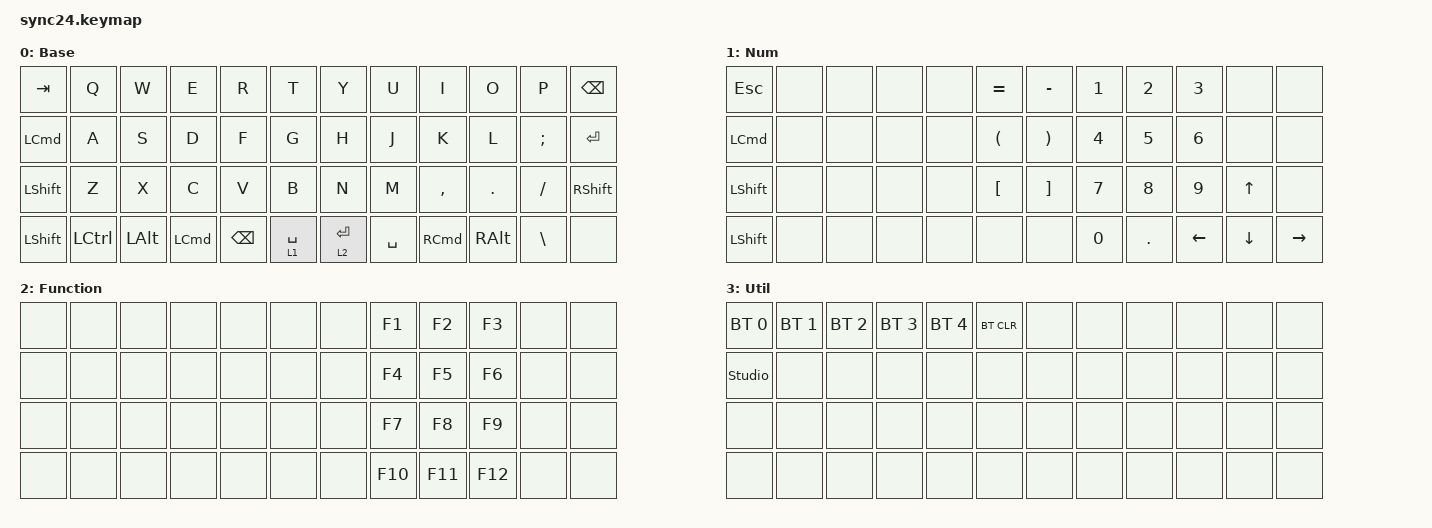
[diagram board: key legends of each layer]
#define ZMK_BEHAVIORS_OMIT_KT

#undef ZMK_BEHAVIORS_KEEP_ALL

#define ZMK_BEHAVIORS_KEEP_SK
#define ZMK_BEHAVIORS_KEEP_MT
#define ZMK_BEHAVIORS_KEEP_KT

#include <behaviors.dtsi>
#include <dt-bindings/zmk/keys.h>
#include <dt-bindings/zmk/bt.h>
#include <dt-bindings/zmk/outputs.h>

// naginata
#include <behaviors/naginata.dtsi>

/ {

// naginata language_1が動くかは分からない
    macros {
      ng_on: ng_on {
        compatible = "zmk,behavior-macro";
        #binding-cells = <0>;
        bindings = <&macro_tap &kp LANGUAGE_1 &kp INTERNATIONAL_4 &to 1>;
      };
      ng_off: ng_off {
        compatible = "zmk,behavior-macro";
        #binding-cells = <0>;
        bindings = <&macro_tap &kp LANGUAGE_2 &kp INTERNATIONAL_5 &to 0>;
      };
    };


    combos {
        compatible = "zmk,combos";

        combo_us {
            timeout-ms = <50>;
            key-positions = <14 15>;
            bindings = <&kp LANG2>;
        };

        combo_kana {
            timeout-ms = <50>;
            key-positions = <20 21>;
            bindings = <&kp LANG1>;
        };

        combo_util {
            timeout-ms = <50>;
            key-positions = <36 37>;
            bindings = <&mo 3>;
        };

// naginata 薙刀への切り替えのFGとオフのHJに割り当て
        combo_ng_on {
          timeout-ms = <300>;
          key-positions = <15 16>;   /* ←ここを書き換える */
          bindings = <&ng_on>;
          layers = <0>;
        };

        combo_ng_off {
          timeout-ms = <300>;
          key-positions = <13 14>;   /* ←ここを書き換える */
          bindings = <&ng_off>;
          layers = <0 1>;
        };

    };

    keymap {
        compatible = "zmk,keymap";

// ▄▄▄▄▄▄▄▄▄▄▄▄▄▄▄▄▄▄▄▄▄▄▄▄▄▄▄▄▄▄▄▄▄▄▄▄▄▄▄▄▄▄▄▄▄▄▄▄▄▄▄▄▄▄▄▄▄▄▄▄▄▄▄▄▄▄▄▄▄▄▄▄▄▄▄▄▄▄▄▄▄▄▄▄▄▄▄▄▄▄▄▄▄▄▄▄▄▄▄▄▄▄▄▄▄▄▄▄▄▄▄▄▄▄▄▄▄▄▄▄▄▄▄▄▄▄▄▄▄▄▄▄▄▄▄▄▄▄▄▄▄▄▄▄▄▄▄▄▄
        base {
            display-name = "Base";
            bindings = <

// ╷           ╷           ╷           ╷           ╷           ╷           ╷   ╷           ╷           ╷           ╷           ╷           ╷           ╷
    &kp TAB    &kp Q       &kp W       &kp E       &kp R       &kp T           &kp Y       &kp U       &kp I       &kp O       &kp P         &kp BACKSPACE 
    &kp LCMD   &kp A       &kp S       &kp D       &kp F       &kp G           &kp H       &kp J       &kp K       &kp L       &kp SEMICOLON &kp RET
    &kp LSHFT  &kp Z       &kp X       &kp C       &kp V       &kp B           &kp N       &kp M       &kp COMMA   &kp DOT     &kp FSLH      &kp RSHIFT
    &kp LSHFT  &kp LCTRL   &kp LALT    &kp LCMD    &kp BSPC    &lt 1 SPACE     &lt 2 RET   &kp SPACE   &kp RCMD    &kp RALT    &kp BSLH      &none

            >;
        };

// ▄▄▄▄▄▄▄▄▄▄▄▄▄▄▄▄▄▄▄▄▄▄▄▄▄▄▄▄▄▄▄▄▄▄▄▄▄▄▄▄▄▄▄▄▄▄▄▄▄▄▄▄▄▄▄▄▄▄▄▄▄▄▄▄▄▄▄▄▄▄▄▄▄▄▄▄▄▄▄▄▄▄▄▄▄▄▄▄▄▄▄▄▄▄▄▄▄▄▄▄▄▄▄▄▄▄▄▄▄▄▄▄▄▄▄▄▄▄▄▄▄▄▄▄▄▄▄▄▄▄▄▄▄▄▄▄▄▄▄▄▄▄▄▄▄▄▄▄▄
        num {
            display-name = "Num";
            bindings = <

// ╷           ╷           ╷           ╷           ╷           ╷           ╷   ╷           ╷           ╷           ╷           ╷           ╷           ╷
    &kp ESC     &none       &none       &none       &none       &kp EQUAL       &kp MINUS   &kp N1      &kp N2      &kp N3         &none          &none
    &kp LCMD    &none       &none       &none       &none       &kp LPAR        &kp RPAR    &kp N4      &kp N5      &kp N6         &none          &none
    &kp LSHFT   &none       &none       &none       &none       &kp LBKT        &kp RBKT    &kp N7      &kp N8      &kp N9         &kp UP_ARROW   &none
    &kp LSHFT   &none       &none       &none       &none       &none           &none       &kp N0      &kp DOT     &kp LEFT_ARROW &kp DOWN_ARROW &kp RIGHT_ARROW

            >;
        };

// ▄▄▄▄▄▄▄▄▄▄▄▄▄▄▄▄▄▄▄▄▄▄▄▄▄▄▄▄▄▄▄▄▄▄▄▄▄▄▄▄▄▄▄▄▄▄▄▄▄▄▄▄▄▄▄▄▄▄▄▄▄▄▄▄▄▄▄▄▄▄▄▄▄▄▄▄▄▄▄▄▄▄▄▄▄▄▄▄▄▄▄▄▄▄▄▄▄▄▄▄▄▄▄▄▄▄▄▄▄▄▄▄▄▄▄▄▄▄▄▄▄▄▄▄▄▄▄▄▄▄▄▄▄▄▄▄▄▄▄▄▄▄▄▄▄▄▄▄▄
        function {
            display-name = "Function";
            bindings = <

// ╷           ╷           ╷           ╷           ╷           ╷           ╷   ╷           ╷           ╷           ╷           ╷           ╷           ╷
    &none       &none       &none       &none       &none       &none           &none       &kp F1      &kp F2      &kp F3      &none       &none
    &none       &none       &none       &none       &none       &none           &none       &kp F4      &kp F5      &kp F6      &none       &none
    &none       &none       &none       &none       &none       &none           &none       &kp F7      &kp F8      &kp F9      &none       &none
    &none       &none       &none       &none       &none       &none           &none       &kp F10     &kp F11     &kp F12     &none       &none
            
            >;
        };


// ▄▄▄▄▄▄▄▄▄▄▄▄▄▄▄▄▄▄▄▄▄▄▄▄▄▄▄▄▄▄▄▄▄▄▄▄▄▄▄▄▄▄▄▄▄▄▄▄▄▄▄▄▄▄▄▄▄▄▄▄▄▄▄▄▄▄▄▄▄▄▄▄▄▄▄▄▄▄▄▄▄▄▄▄▄▄▄▄▄▄▄▄▄▄▄▄▄▄▄▄▄▄▄▄▄▄▄▄▄▄▄▄▄▄▄▄▄▄▄▄▄▄▄▄▄▄▄▄▄▄▄▄▄▄▄▄▄▄▄▄▄▄▄▄▄▄▄▄▄
        util {
            display-name = "Util";
            bindings = <

// ╷               ╷           ╷           ╷           ╷           ╷           ╷   ╷           ╷           ╷           ╷           ╷           ╷           ╷
    &bt BT_SEL 0    &bt BT_SEL 1&bt BT_SEL 2&bt BT_SEL 3&bt BT_SEL 4&bt BT_CLR      &none       &none       &none       &none       &none       &none
    &studio_unlock  &none       &none       &none       &none       &none           &none       &none       &none       &none       &none       &none
    &none           &none       &none       &none       &none       &none           &none       &none       &none       &none       &none       &none
    &none           &none       &none       &none       &none       &none           &none       &none       &none       &none       &none       &none
            
            >;
        };

// ▄▄▄▄▄▄▄▄▄▄▄▄▄▄▄▄▄▄▄▄▄▄▄▄▄▄▄▄▄▄▄▄▄▄▄▄▄▄▄▄▄▄▄▄▄▄▄▄▄▄▄▄▄▄▄▄▄▄▄▄▄▄▄▄▄▄▄▄▄▄▄▄▄▄▄▄▄▄▄▄▄▄▄▄▄▄▄▄▄▄▄▄▄▄▄▄▄▄▄▄▄▄▄▄▄▄▄▄▄▄▄▄▄▄▄▄▄▄▄▄▄▄▄▄▄▄▄▄▄▄▄▄▄▄▄▄▄▄▄▄▄▄▄▄▄▄▄▄▄
        extra1 {
            status = "reserved";
            bindings = <

// ╷           ╷           ╷           ╷           ╷           ╷           ╷   ╷           ╷           ╷           ╷           ╷           ╷           ╷
    &none       &none       &none       &none       &none       &none           &none       &none       &none       &none       &none       &none
    &none       &none       &none       &none       &none       &none           &none       &none       &none       &none       &none       &none
    &none       &none       &none       &none       &none       &none           &none       &none       &none       &none       &none       &none
    &none       &none       &none       &none       &none       &none           &none       &none       &none       &none       &none       &none
            
            >;
        };

// ▄▄▄▄▄▄▄▄▄▄▄▄▄▄▄▄▄▄▄▄▄▄▄▄▄▄▄▄▄▄▄▄▄▄▄▄▄▄▄▄▄▄▄▄▄▄▄▄▄▄▄▄▄▄▄▄▄▄▄▄▄▄▄▄▄▄▄▄▄▄▄▄▄▄▄▄▄▄▄▄▄▄▄▄▄▄▄▄▄▄▄▄▄▄▄▄▄▄▄▄▄▄▄▄▄▄▄▄▄▄▄▄▄▄▄▄▄▄▄▄▄▄▄▄▄▄▄▄▄▄▄▄▄▄▄▄▄▄▄▄▄▄▄▄▄▄▄▄▄
        extra2 {
            status = "reserved";
            bindings = <

// ╷           ╷           ╷           ╷           ╷           ╷           ╷   ╷           ╷           ╷           ╷           ╷           ╷           ╷
    &none       &none       &none       &none       &none       &none           &none       &none       &none       &none       &none       &none
    &none       &none       &none       &none       &none       &none           &none       &none       &none       &none       &none       &none
    &none       &none       &none       &none       &none       &none           &none       &none       &none       &none       &none       &none
    &none       &none       &none       &none       &none       &none           &none       &none       &none       &none       &none       &none
            
            >;
        };

    };
};
